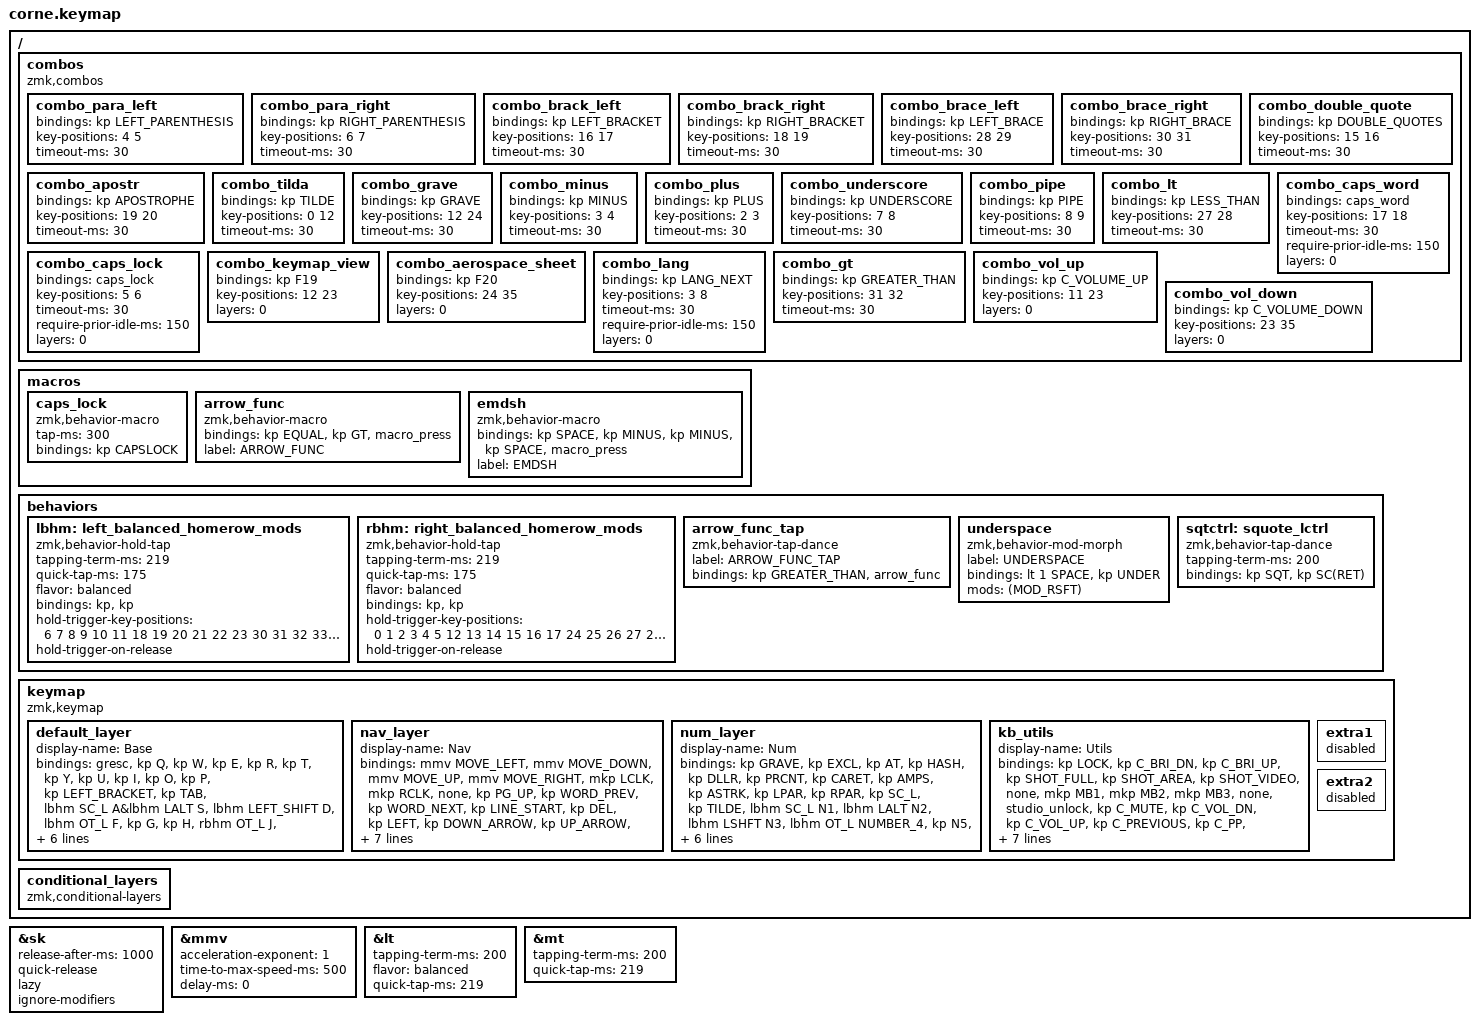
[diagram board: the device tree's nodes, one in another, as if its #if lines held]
/*
 * Copyright (c) 2020 The ZMK Contributors
 *
 * ==============================================================================
 * Corne Keyboard (CRKBD) - Row-First (Horizontal) Key Indexing
 * ==============================================================================
 *
 * Description:
 * Indexing starts at 0 and proceeds from left to right across the entire row,
 * spanning both halves, before moving down to the next row. This method
 * is commonly used in firmware like ZMK.
 *
 *
 * ------------------------------ MAIN CLUSTER ------------------------------
 *
 * Row 0 (Top): Indices 0 - 11
 *                  <---------- Left Half ------->    <-------- Right Half --------->
 *                  ┌────┬────┬────┬────┬────┬────┐   ┌────┬────┬────┬────┬────┬────┐
 *                  │ 00 │ 01 │ 02 │ 03 │ 04 │ 05 │   │ 06 │ 07 │ 08 │ 09 │ 10 │ 11 │
 *                  ├────┼────┼────┼────┼────┼────┤   ├────┼────┼────┼────┼────┼────┤
 *                  │ 12 │ 13 │ 14 │ 15 │ 16 │ 17 │   │ 18 │ 19 │ 20 │ 21 │ 22 │ 23 │
 *                  ├────┼────┼────┼────┼────┼────┤   ├────┼────┼────┼────┼────┼────┤
 *                  │ 24 │ 25 │ 26 │ 27 │ 28 │ 29 │   │ 30 │ 31 │ 32 │ 33 │ 34 │ 35 │
 *                  └────┴────┴────┴────┴────┴────┘   └────┴────┴────┴────┴────┴────┘
 *
 *
 * ----------------------------- THUMB CLUSTERS -----------------------------
 *
 * Row 3 (Thumbs): Indices 36 - 41
 *                                <- Left Cluster ->  <- Right Cluster ->
 *                                 ┌────┬────┬────┐   ┌────┬────┬────┐
 *                                 │ 36 │ 37 │ 38 │   │ 39 │ 40 │ 41 │
 *                                 └────┴────┴────┘   └────┴────┴────┘
 *
 *
 * Index Range Summary:
 * -----------------------------
 *  - Top Row:       0 - 11
 *  - Home Row:     12 - 23
 *  - Bottom Row:   24 - 35
 *  - Thumb Cluster: 36 - 41
 * -----------------------------
 *  Total Keys: 42 (indices 0 through 41)
 *
 */

#define ZMK_POINTING_DEFAULT_MOVE_VAL 800  // default: 600
#define ZMK_POINTING_DEFAULT_SCRL_VAL 20    // default: 10

#include <zmk-helpers/key-labels/42.h>
#include <behaviors.dtsi>
#include <dt-bindings/zmk/bt.h>
#include <dt-bindings/zmk/keys.h>
#include <dt-bindings/zmk/pointing.h>

/*
 * ==============================================================================
 * Target OS
 * ==============================================================================
 *
 * Requirement: the computer keeps its default settings. No modifier swaps,
 * no remapped keys, no custom system shortcuts in the OS. Everything that
 * differs between operating systems is defined here, and the layers below
 * use only these names.
 *
 * The OS is chosen at build time: build.yaml passes
 * -DDTS_EXTRA_CPPFLAGS=-DOS_MAC (or -DOS_LINUX) to the central part (dongle,
 * or the left half without a dongle). Peripherals compile the keymap but
 * don't use it, so they have one build for both (built with OS_LINUX).
 *
 * Modifiers by role, not by name:
 *   SC   the shortcut modifier (copy, paste, save...): Cmd on macOS,
 *        Ctrl on Linux. Pinky (A, ;) and the left thumb: pinky + thumb
 *        gives SC+Tab / SC+Space / SC+Backspace.
 *   OT   the other one: Ctrl on macOS, Super on Linux. Index finger (F, J).
 *        (The hold of the Enter thumb is Hyper, not OT.)
 * Home-row mods resolve as hold with a key of the other hand or with any
 * thumb key (hold-trigger-key-positions), so pinky + thumb of one hand works.
 *
 * System actions use the OS default shortcuts:
 *   macOS: Cmd+Shift+3/4/5 screenshots, Ctrl+Cmd+Q lock, Ctrl+arrows for
 *          Mission Control / App windows / Spaces.
 *   Linux: GNOME defaults: Shift+Print / Print / Ctrl+Alt+Shift+R,
 *          Super+L lock, Super = overview, Ctrl+Alt+arrows workspaces.
 */
#if defined(OS_MAC)
#define SC_L        LGUI
#define SC_R        RGUI
#define OT_L        LCTRL
#define OT_R        RCTRL
#define SC(k)       LG(k)
#define OT(k)       LC(k)
#define SHOT_FULL   LG(LS(N3))
#define SHOT_AREA   LG(LS(N4))
#define SHOT_VIDEO  LG(LS(N5))          /* screenshot panel, has screen recording */
#define LOCK        LC(LG(Q))
#define OVERVIEW    LC(UP)              /* Mission Control */
#define APP_WINS    LC(DOWN)            /* App windows (App Exposé) */
#define DESK_PREV   LC(LEFT)            /* previous Space */
#define DESK_NEXT   LC(RIGHT)           /* next Space */
/* Switch input source: F18, unused on macOS. Karabiner turns it into the
 * Globe key (macos/karabiner/corne-lang-switch.json): macOS ignores the
 * consumer usage that stands for Globe on other keyboards (0x029D). */
#define LANG_NEXT   F18
#define WORD_PREV   LA(LEFT)
#define WORD_NEXT   LA(RIGHT)
#define LINE_START  LG(LEFT)            /* Home/End scroll the document on macOS */
#define LINE_END    LG(RIGHT)
#define DOC_START   LG(UP)
#define DOC_END     LG(DOWN)
#elif defined(OS_LINUX)
#define SC_L        LCTRL
#define SC_R        RCTRL
#define OT_L        LGUI
#define OT_R        RGUI
#define SC(k)       LC(k)
#define OT(k)       LG(k)
#define SHOT_FULL   LS(PSCRN)
#define SHOT_AREA   PSCRN               /* GNOME screenshot UI: area, window, screen */
#define SHOT_VIDEO  LC(LA(LS(R)))       /* GNOME screencast UI */
#define LOCK        LG(L)
#define OVERVIEW    LGUI                /* Activities overview */
#define APP_WINS    LG(A)               /* app grid: GNOME has no app-windows view */
#define DESK_PREV   LC(LA(LEFT))
#define DESK_NEXT   LC(LA(RIGHT))
#define LANG_NEXT   LG(SPACE)           /* GNOME: next input source */
#define WORD_PREV   LC(LEFT)
#define WORD_NEXT   LC(RIGHT)
#define LINE_START  HOME
#define LINE_END    END
#define DOC_START   LC(HOME)
#define DOC_END     LC(END)
#else
#error "Build with -DDTS_EXTRA_CPPFLAGS=-DOS_MAC or -DOS_LINUX (cmake-args in build.yaml)"
#endif

/* Same on both systems */
#define UNDO        SC(Z)
#define CUT         SC(X)
#define COPY        SC(C)
#define PASTE       SC(V)
#define REDO        SC(LS(Z))
/* Hyper = all four modifiers: free on both systems, for shortcuts bound in the
 * OS or in AeroSpace (README: "App launch shortcuts"). Held on either thumb:
 * Del (right) or Enter (left), so letters of both halves are reachable. */
#define HYPER       LC(LA(LS(LGUI)))


&sk {
    release-after-ms = <1000>;
    quick-release;
    lazy;
    ignore-modifiers;
};

&mmv {
    acceleration-exponent = <1>;          // 1
    time-to-max-speed-ms = <500>;         // 300
    delay-ms = <0>;                       // 0
};

&lt {
    tapping-term-ms = <200>; // default 200
    flavor = "balanced"; // or hold-preferred or tap-preferred
    quick-tap-ms = <219>;
};

&mt {
    tapping-term-ms = <200>; // default 200
    quick-tap-ms = <219>;
};

/ {
    combos {
        compatible = "zmk,combos";

        // -- parenthesis and brackets

        combo_para_left {
            bindings = <&kp LEFT_PARENTHESIS>;
            key-positions = <4 5>;
            timeout-ms = <30>;
        };

        combo_para_right {
            bindings = <&kp RIGHT_PARENTHESIS>;
            key-positions = <6 7>;
            timeout-ms = <30>;
        };

        combo_brack_left {
            bindings = <&kp LEFT_BRACKET>;
            key-positions = <16 17>;
            timeout-ms = <30>;
        };

        combo_brack_right {
            bindings = <&kp RIGHT_BRACKET>;
            key-positions = <18 19>;
            timeout-ms = <30>;
        };

        combo_brace_left {
            bindings = <&kp LEFT_BRACE>;
            key-positions = <28 29>;
            timeout-ms = <30>;
        };

        combo_brace_right {
            bindings = <&kp RIGHT_BRACE>;
            key-positions = <30 31>;
            timeout-ms = <30>;
        };

        //

        combo_double_quote {
            bindings = <&kp DOUBLE_QUOTES>;
            key-positions = <15 16>;
            timeout-ms = <30>;
        };

        combo_apostr {
            bindings = <&kp APOSTROPHE>;
            key-positions = <19 20>;
            timeout-ms = <30>;
        };

        combo_tilda {
            bindings = <&kp TILDE>;
            key-positions = <0 12>;
            timeout-ms = <30>;
        };

        combo_grave {
            bindings = <&kp GRAVE>;
            key-positions = <12 24>;
            timeout-ms = <30>;
        };

        combo_minus {
            bindings = <&kp MINUS>;
            key-positions = <3 4>;
            timeout-ms = <30>;
        };

        combo_plus {
            bindings = <&kp PLUS>;
            key-positions = <2 3>;
            timeout-ms = <30>;
        };

        combo_underscore {
            bindings = <&kp UNDERSCORE>;
            key-positions = <7 8>;
            timeout-ms = <30>;
        };

        combo_pipe {
            bindings = <&kp PIPE>;
            key-positions = <8 9>;
            timeout-ms = <30>;
        };

        combo_lt {
            bindings = <&kp LESS_THAN>;
            key-positions = <27 28>;
            timeout-ms = <30>;
        };

        // Caps word (G+H) and Caps Lock (T+Y): one key of each hand, and both
        // pairs roll in ordinary words ("right", "pretty"). Same timing as the
        // language combo: a short window, and only after a pause in typing.
        combo_caps_word {
            bindings = <&caps_word>;
            key-positions = <17 18>;
            timeout-ms = <30>;
            require-prior-idle-ms = <150>;
            layers = <0>;
        };

        combo_caps_lock {
            bindings = <&caps_lock>;
            key-positions = <5 6>;
            timeout-ms = <30>;
            require-prior-idle-ms = <150>;
            layers = <0>;
        };

        // Show / hide the keymap picture: outer keys of the middle row.
        // F19 is unused on both systems; the OS runs scripts/keymap-view.sh
        // on it (macOS: Karabiner rule, GNOME: custom shortcut).
        combo_keymap_view {
            bindings = <&kp F19>;
            key-positions = <12 23>;
            layers = <0>;
        };

        // Show / hide the AeroSpace cheat sheet: the two outer keys of the
        // bottom row (sticky Shifts). F20 is unused on both systems; AeroSpace
        // binds it in ~/.aerospace.toml (dotfiles repo) to a script.
        combo_aerospace_sheet {
            bindings = <&kp F20>;
            key-positions = <24 35>;
            layers = <0>;
        };


        // Switch input source: E + I (top row, one key of each hand). Fast
        // typing rolls e and i of words like "their" within the timeout, so
        // the combo fires only after a pause in typing.
        combo_lang {
            bindings = <&kp LANG_NEXT>;
            key-positions = <3 8>;
            timeout-ms = <30>;
            require-prior-idle-ms = <150>;
            layers = <0>;
        };

        combo_gt {
            bindings = <&kp GREATER_THAN>;
            key-positions = <31 32>;
            timeout-ms = <30>;
        };

        combo_vol_up {
            bindings = <&kp C_VOLUME_UP>;
            key-positions = <11 23>;
            layers = <0>;
        };

        combo_vol_down {
            bindings = <&kp C_VOLUME_DOWN>;
            key-positions = <23 35>;
            layers = <0>;
        };


        // combo_em-dash {
        //     bindings = <&emdsh>;
        //     key-positions = <2 3 4>;
        //     layers = <0>;
        // };
    };

    macros {
        // Caps Lock held for a fixed time, however short the combo is.
        // macOS ignores a Caps Lock press shorter than ~100 ms, and with
        // "Use Caps Lock to switch to and from ABC" a short press switches
        // the input source instead. 300 ms stays under the key repeat delay.
        caps_lock: caps_lock {
            compatible = "zmk,behavior-macro";
            #binding-cells = <0>;
            tap-ms = <300>;
            bindings = <&kp CAPSLOCK>;
        };

        arrow_func: arrow_func {
            compatible = "zmk,behavior-macro";
            #binding-cells = <0>;
            bindings = <&kp EQUAL &kp GT>, <&macro_press>;

            label = "ARROW_FUNC";
        };

        emdsh: emdsh {
            compatible = "zmk,behavior-macro";
            #binding-cells = <0>;
            bindings =
                <&kp SPACE &kp MINUS &kp MINUS &kp SPACE>,
                <&macro_press>;

            label = "EMDSH";
        };
    };

    behaviors {
        lbhm: left_balanced_homerow_mods {
            compatible = "zmk,behavior-hold-tap";
            #binding-cells = <2>;
            tapping-term-ms = <219>;    // <---[[moderate duration]]
            quick-tap-ms = <175>;
            flavor = "balanced";
            bindings = <&kp>, <&kp>;
            hold-trigger-key-positions = < 6 7 8 9 10 11 18 19 20 21 22 23 30 31 32 33 34 35 36 37 38 39 40 41 >;
            hold-trigger-on-release;
        };

        rbhm: right_balanced_homerow_mods {
            compatible = "zmk,behavior-hold-tap";
            #binding-cells = <2>;
            tapping-term-ms = <219>;    // <---[[moderate duration]]
            quick-tap-ms = <175>;
            flavor = "balanced";
            bindings = <&kp>, <&kp>;
            hold-trigger-key-positions = < 0 1 2 3 4 5 12 13 14 15 16 17 24 25 26 27 28 29 36 37 38 39 40 41 >;
            hold-trigger-on-release;
        };

        arrow_func_tap: arrow_func_tap {
            compatible = "zmk,behavior-tap-dance";
            label = "ARROW_FUNC_TAP";
            #binding-cells = <0>;
            bindings = <&kp GREATER_THAN>, <&arrow_func>;
        };

        underspace: underspace {
            compatible = "zmk,behavior-mod-morph";
            label = "UNDERSPACE";
            bindings = <&lt 1 SPACE>, <&kp UNDER>;

            #binding-cells = <0>;
            mods = <(MOD_RSFT)>;
        };

        sqtctrl: squote_lctrl {
            compatible = "zmk,behavior-tap-dance";
            #binding-cells = <0>;
            tapping-term-ms = <200>;
            bindings = <&kp SQT>, <&kp SC(RET)>;
        };
    };

    keymap {
        compatible = "zmk,keymap";

        default_layer {
            display-name = "Base";
            bindings = <
&gresc     &kp Q         &kp W            &kp E              &kp R         &kp T        &kp Y           &kp U            &kp I               &kp O            &kp P                 &kp LEFT_BRACKET
&kp TAB    &lbhm SC_L A&lbhm LALT S  &lbhm LEFT_SHIFT D  &lbhm OT_L F   &kp G        &kp H           &rbhm OT_L J      &rbhm RSHIFT K  &rbhm LALT L  &rbhm SC_R SEMICOLON  &sqtctrl
&sk LSHFT  &kp Z         &kp X            &kp C              &kp V         &kp B        &kp N           &kp M            &kp COMMA           &kp DOT          &kp FSLH              &sk RSHIFT
                                          &kp SC_L           &lt 2 TAB     &mt HYPER RET &underspace     &lt 3 BACKSPACE  &mt HYPER DEL
            >;
        };
        nav_layer {
            display-name = "Nav";
            // Right hand: arrows on H J K L (as in vim), desktops after them on
            // ; and '; page, word, line and document moves above and below.
            bindings = <
&mmv MOVE_LEFT     &mmv MOVE_DOWN  &mmv MOVE_UP    &mmv MOVE_RIGHT  &mkp LCLK          &mkp RCLK            &none              &kp PG_UP       &kp WORD_PREV   &kp WORD_NEXT    &kp LINE_START     &kp DEL
&kp LEFT           &kp DOWN_ARROW  &kp UP_ARROW    &kp RIGHT        &kp OVERVIEW       &kp APP_WINS         &kp LEFT           &kp DOWN_ARROW  &kp UP_ARROW    &kp RIGHT        &kp DESK_PREV      &kp DESK_NEXT
&mkp MB4           &kp UNDO        &kp CUT         &kp COPY         &kp PASTE          &kp REDO             &mkp MB4           &kp PG_DN       &kp DOC_START   &kp DOC_END      &kp LINE_END       &mkp MB5
                                                   &trans           &trans             &trans               &trans             &trans          &trans
            >;
        };

        num_layer {
            display-name = "Num";
            bindings = <
&kp GRAVE      &kp EXCL       &kp AT       &kp HASH      &kp DLLR     &kp PRCNT         &kp CARET     &kp AMPS      &kp ASTRK      &kp LPAR      &kp RPAR      &kp SC_L
&kp TILDE   &lbhm SC_L N1      &lbhm LALT  N2      &lbhm LSHFT N3      &lbhm OT_L NUMBER_4   &kp N5             &kp N6     &rbhm OT_R NUMBER_7   &rbhm RSHIFT N8      &rbhm RALT N9      &rbhm SC_R N0      &trans
&kp LSHFT   &none       &none       &none       &kp OT(F11)          &kp OT(F12)      &none       &kp KP_EQUAL         &none       &none       &kp BSLH    &kp F10
                                    &none       &none                &none              &kp KP_N1   &kp KP_N2            &kp KP_N3
            >;
        };

        kb_utils {
            display-name = "Utils";
            bindings = <
&kp LOCK     &kp C_BRI_DN    &kp C_BRI_UP  &kp SHOT_FULL     &kp SHOT_AREA &kp SHOT_VIDEO  &none            &mkp MB1        &mkp MB2        &mkp MB3          &none        &studio_unlock
&kp C_MUTE   &kp C_VOL_DN    &kp C_VOL_UP  &kp C_PREVIOUS    &kp C_PP      &kp C_NEXT      &mmv MOVE_LEFT  &mmv MOVE_DOWN  &mmv MOVE_UP    &mmv MOVE_RIGHT   &none        &none
&bt BT_CLR   &bt BT_SEL 0    &bt BT_SEL 1  &bt BT_SEL 2      &bt BT_SEL 3  &bt BT_SEL 4    &none            &mkp MB4        &msc SCRL_DOWN  &msc SCRL_UP      &mkp MB5     &none
                                           &none             &none         &none           &mkp MB1         &mkp MB2        &none
            >;
        };

        // Empty layers for ZMK Studio: hidden in regular builds,
        // available to fill in Studio-enabled builds.
        extra1 {
            status = "reserved";
        };

        extra2 {
            status = "reserved";
        };
    };

    conditional_layers { compatible = "zmk,conditional-layers"; };
};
